AUTOSAR XML (schema 4-3-0)
package /CountingLogicF/Components
  composition sw component type Application
    component consumer: type=CountConsumer
    component counter: type=Counter
    component generator: type=CountAlterer
    connect counter.control -> generator.alterCount
    connect counter.data -> consumer.readCount
  application sw component type CountAlterer
    require port alterCount: required-interface=CounterControlInterface
  complex device driver sw component type CountConsumer
    require port readCount: queued-receiver-com-spec{data-element=count, queue-length=5}, required-interface=CounterDataInterface
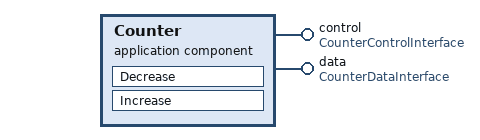
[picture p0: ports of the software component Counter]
  application sw component type Counter
    provide port control: provided-interface=CounterControlInterface
    provide port data: queued-sender-com-spec{data-element=count, handle-out-of-range=SATURATE}, provided-interface=CounterDataInterface
    behavior ib
      operation invoked event onDecrease: start-on-event=Decrease, operation=control.decrease
      operation invoked event onIncrease: start-on-event=Increase, operation=control.increase
      explicit-inter-runnable-variables:
        data current: type=CounterDataType
      runnable Decrease
        data-send-points:
          access send: accessed-variable=data.count
        read-local-variables:
          access readCurrent: accessed-variable=current
        written-local-variables:
          access writeCurrent: accessed-variable=current
      runnable Increase
        data-send-points:
          access send: accessed-variable=data.count
        read-local-variables:
          access readCurrent: accessed-variable=current
        written-local-variables:
          access writeCurrent: accessed-variable=current
package /CountingLogicF/DataTypes
  app type CounterDataType: category=VALUE, data-constr=CounterDataType_sizeLimits
  impl type CounterDataTypeImpl: category=VALUE, data-constr=CounterDataType_sizeLimits
  range CounterDataType_sizeLimits: phys 0..100, raw 0..100
  data type mapping set dataTypeMappingSet: data-type-map{application-data-type=CounterDataType, implementation-data-type=CounterDataTypeImpl}
package /CountingLogicF/Interfaces
  client server interface CounterControlInterface
    operation decrease
      arg delta: type=CounterDataType, direction=IN
      arg result: type=CounterDataType, direction=OUT
    operation increase
      arg delta: type=CounterDataType, direction=IN
      arg result: type=CounterDataType, direction=OUT
  sender receiver interface CounterDataInterface
    data count: sw-impl-policy=QUEUED, type=CounterDataType
